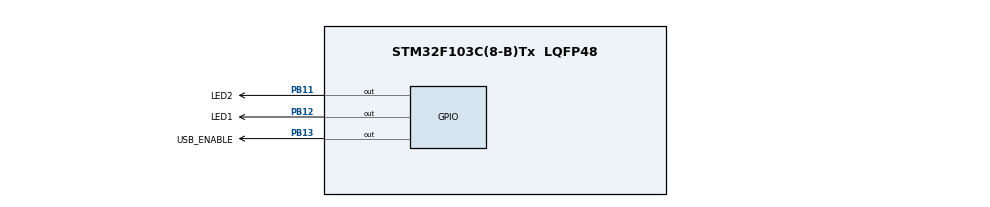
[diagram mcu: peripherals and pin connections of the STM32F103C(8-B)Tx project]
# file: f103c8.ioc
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Mcu.Family=STM32F1
Mcu.Name=STM32F103C(8-B)Tx
Mcu.Package=LQFP48
NVIC.PriorityGroup=NVIC_PRIORITYGROUP_4
PA13.Mode=Serial_Wire
PA13.Signal=SYS_JTMS-SWDIO
PA14.Mode=Serial_Wire
PA14.Signal=SYS_JTCK-SWCLK
PB11.GPIO_Label=LED2
PB11.Signal=GPIO_Output
PB12.GPIO_Label=LED1
PB12.Signal=GPIO_Output
PB13.GPIO_Label=USB_ENABLE
PB13.Signal=GPIO_Output
PD0-OSC_IN.Mode=HSE-External-Oscillator
PD0-OSC_IN.Signal=RCC_OSC_IN
PD1-OSC_OUT.Mode=HSE-External-Oscillator
PD1-OSC_OUT.Signal=RCC_OSC_OUT
ProjectManager.HeapSize=0x200
ProjectManager.StackSize=0x400
ProjectManager.TargetToolchain=SW4STM32
RCC.AHBFreq_Value=72000000
RCC.APB1CLKDivider=RCC_HCLK_DIV2
RCC.APB1Freq_Value=36000000
RCC.APB1TimFreq_Value=72000000
RCC.APB2Freq_Value=72000000
RCC.APB2TimFreq_Value=72000000
RCC.EnbaleCSS=true
RCC.HCLKFreq_Value=72000000
RCC.PLLMUL=RCC_PLL_MUL9
RCC.PLLSourceVirtual=RCC_PLLSOURCE_HSE
RCC.SYSCLKFreq_VALUE=72000000
RCC.SYSCLKSource=RCC_SYSCLKSOURCE_PLLCLK
RCC.USBFreq_Value=48000000
RCC.USBPrescaler=RCC_USBCLKSOURCE_PLL_DIV1_5
board=custom

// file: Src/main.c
/* USER CODE BEGIN Header */
/**
  ******************************************************************************
  * @file           : main.c
  * @brief          : Main program body
  ******************************************************************************
  ** This notice applies to any and all portions of this file
  * that are not between comment pairs USER CODE BEGIN and
  * USER CODE END. Other portions of this file, whether
  * inserted by the user or by software development tools
  * are owned by their respective copyright owners.
  *
  * COPYRIGHT(c) 2018 STMicroelectronics
  *
  * Redistribution and use in source and binary forms, with or without modification,
  * are permitted provided that the following conditions are met:
  *   1. Redistributions of source code must retain the above copyright notice,
  *      this list of conditions and the following disclaimer.
  *   2. Redistributions in binary form must reproduce the above copyright notice,
  *      this list of conditions and the following disclaimer in the documentation
  *      and/or other materials provided with the distribution.
  *   3. Neither the name of STMicroelectronics nor the names of its contributors
  *      may be used to endorse or promote products derived from this software
  *      without specific prior written permission.
  *
  * THIS SOFTWARE IS PROVIDED BY THE COPYRIGHT HOLDERS AND CONTRIBUTORS "AS IS"
  * AND ANY EXPRESS OR IMPLIED WARRANTIES, INCLUDING, BUT NOT LIMITED TO, THE
  * IMPLIED WARRANTIES OF MERCHANTABILITY AND FITNESS FOR A PARTICULAR PURPOSE ARE
  * DISCLAIMED. IN NO EVENT SHALL THE COPYRIGHT HOLDER OR CONTRIBUTORS BE LIABLE
  * FOR ANY DIRECT, INDIRECT, INCIDENTAL, SPECIAL, EXEMPLARY, OR CONSEQUENTIAL
  * DAMAGES (INCLUDING, BUT NOT LIMITED TO, PROCUREMENT OF SUBSTITUTE GOODS OR
  * SERVICES; LOSS OF USE, DATA, OR PROFITS; OR BUSINESS INTERRUPTION) HOWEVER
  * CAUSED AND ON ANY THEORY OF LIABILITY, WHETHER IN CONTRACT, STRICT LIABILITY,
  * OR TORT (INCLUDING NEGLIGENCE OR OTHERWISE) ARISING IN ANY WAY OUT OF THE USE
  * OF THIS SOFTWARE, EVEN IF ADVISED OF THE POSSIBILITY OF SUCH DAMAGE.
  *
  ******************************************************************************
  */
/* USER CODE END Header */

#include <usbd_cdc_if.h>
#include "main.h"
#include "usb_device.h"

void SystemClock_Config(void);
static void MX_GPIO_Init(void);

int main(void)
{

  /* MCU Configuration--------------------------------------------------------*/

  /* Reset of all peripherals, Initializes the Flash interface and the Systick. */
  HAL_Init();

  /* Configure the system clock */
  SystemClock_Config();

  /* Initialize all configured peripherals */
  MX_GPIO_Init();
  MX_USB_DEVICE_Init();

  /* Infinite loop */
  /* USER CODE BEGIN WHILE */
  LL_GPIO_TogglePin(GPIOB, LL_GPIO_PIN_11);
  uint8_t CDC_BUF[128];
  CDC_BUF[0]  = 'H';
  CDC_BUF[1]  = 'E';
  CDC_BUF[2]  = 'L';
  CDC_BUF[3]  = 'L';
  CDC_BUF[4]  = 'O';
  CDC_BUF[5]  = ' ';
  CDC_BUF[6]  = 'C';
  CDC_BUF[7]  = 'D';
  CDC_BUF[8]  = 'C';
  CDC_BUF[9]  = '\r';
  CDC_BUF[10] = '\n';

#pragma clang diagnostic ignored "-Wmissing-noreturn"
  while (1)
  {

    LL_mDelay(300);
    LL_GPIO_TogglePin(GPIOB, LL_GPIO_PIN_11 | LL_GPIO_PIN_12);
    // Stuff the buffer

    CDC_Transmit_FS(CDC_BUF,11);
    /* USER CODE END WHILE */

  }
}

void SystemClock_Config(void)
{
  LL_FLASH_SetLatency(LL_FLASH_LATENCY_2);

   if(LL_FLASH_GetLatency() != LL_FLASH_LATENCY_2)
  {
    Error_Handler();
  }
  LL_RCC_HSE_Enable();

   /* Wait till HSE is ready */
  while(LL_RCC_HSE_IsReady() != 1)
  {

  }
  LL_RCC_HSE_EnableCSS();
  LL_RCC_PLL_ConfigDomain_SYS(LL_RCC_PLLSOURCE_HSE_DIV_1, LL_RCC_PLL_MUL_9);
  LL_RCC_PLL_Enable();

   /* Wait till PLL is ready */
  while(LL_RCC_PLL_IsReady() != 1)
  {

  }
  LL_RCC_SetAHBPrescaler(LL_RCC_SYSCLK_DIV_1);
  LL_RCC_SetAPB1Prescaler(LL_RCC_APB1_DIV_2);
  LL_RCC_SetAPB2Prescaler(LL_RCC_APB2_DIV_1);
  LL_RCC_SetSysClkSource(LL_RCC_SYS_CLKSOURCE_PLL);

   /* Wait till System clock is ready */
  while(LL_RCC_GetSysClkSource() != LL_RCC_SYS_CLKSOURCE_STATUS_PLL)
  {

  }
  LL_Init1msTick(72000000);
  LL_SYSTICK_SetClkSource(LL_SYSTICK_CLKSOURCE_HCLK);
  LL_SetSystemCoreClock(72000000);
  LL_RCC_SetUSBClockSource(LL_RCC_USB_CLKSOURCE_PLL_DIV_1_5);
}

static void MX_GPIO_Init(void)
{
  LL_GPIO_InitTypeDef GPIO_InitStruct = {0};

  /* GPIO Ports Clock Enable */
  LL_APB2_GRP1_EnableClock(LL_APB2_GRP1_PERIPH_GPIOD);
  LL_APB2_GRP1_EnableClock(LL_APB2_GRP1_PERIPH_GPIOB);
  LL_APB2_GRP1_EnableClock(LL_APB2_GRP1_PERIPH_GPIOA);

  /**/
  LL_GPIO_ResetOutputPin(GPIOB, LED2_Pin|LED1_Pin|USB_ENABLE_Pin);

  /**/
  GPIO_InitStruct.Pin = LED2_Pin|LED1_Pin|USB_ENABLE_Pin;
  GPIO_InitStruct.Mode = LL_GPIO_MODE_OUTPUT;
  GPIO_InitStruct.Speed = LL_GPIO_SPEED_FREQ_LOW;
  GPIO_InitStruct.OutputType = LL_GPIO_OUTPUT_PUSHPULL;
  LL_GPIO_Init(GPIOB, &GPIO_InitStruct);

}

void Error_Handler(void)
{
}

/************************ (C) COPYRIGHT STMicroelectronics *****END OF FILE****/
